# TC37XPD register map
Vendor: Infineon; Series: ATVMC; File version: 100
CPU: other r0p0, little endian, MPU, FPU, vendor SysTick, 4 interrupt priority bits
Registers are 32-bit, read-write, reset 0x0 unless marked. A register's access mark holds for its fields unless they carry their own. Offsets are from the block's base; [hi:lo] are bit positions; lines under a group give offsets from that group; {n}, {i} and the like mark numbered series.

## CBS
Base 0xF0000400
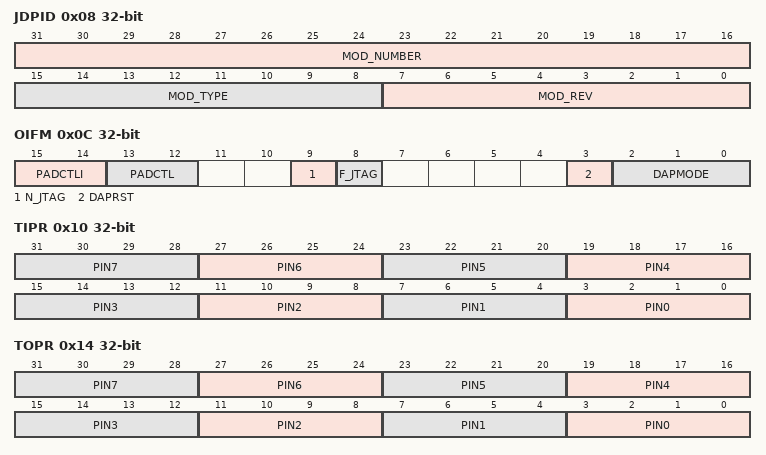
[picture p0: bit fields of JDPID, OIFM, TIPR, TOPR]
0x08 JDPID ro reset not defined — Module Identification Register resetvalue={PowerOn Reset:0x6360,Application Reset:0x0,Debug Reset:0x0,IOClient Reset:0x0}
  [31:16] MOD_NUMBER — Module Number MOD NUMBER
  [15:8] MOD_TYPE — Module Type MOD TYPE
  [7:0] MOD_REV — Module Revision MOD REV. This bit field indicates the revision number of the module implementation. It is just CROSSREFERENCE 7 0 .
0x0C OIFM reset not defined — OCDS Interface Mode Register resetvalue={PowerOn Reset:0x0,Application Reset:0x0,Debug Reset:0x0,IOClient Reset:0x0}
  [15:14] PADCTLI — Pad input threshold control for Debug Interface Pins. DAP pins always use TTL levels. This bits allows to set correct TTL levels even for 3.3V supply. Selection valid for DAP and DAPE pads.
  [13:12] PADCTL — Pad Control for Debug Interface Pins. padctl o Please consult the Data Sheet for the proper setting relative to the data rate. Selection valid for DAP and DAPE pads.
  [9] N_JTAG — No Switch to JTAG. jtag disable o
  [8] F_JTAG — Forced JTAG Mode. dap bypass o
  [3] DAPRST — DAPProtocol Clear DAPRST. Synchronous clear for the DAP state machine. See CROSSREFERENCE . Once set this bit is cleared by the hardware as soon as the DAP module has processed the reset request. As this is done with the DAP0 clock the time it takes is not predictable.
  [2:0] DAPMODE — DAPInterface Mode DAPMODE. DAPMODE mainly determines the number of pins allocated for the DAP Interface. The selected mode becomes active with the next received CROSSREFERENCE . The minimum number of dedicated DAP pins is device specific. If two pins are dedicated no SPD Single Pin DAP mode is needed offered. Please request DAP RST in parallel only if it is really needed and intended to force the selected mode and cut by this an already established tool connection. The underlying assumption is that the tool user is in control and the device should not sabotage tool access.
0x10 TIPR — TG Input Pins Routing resetvalue={Debug Reset:0x0}
  [4n+3:4n] PIN{n} (n=0..7) — Trigger Pin 7 to Trigger Line Routing
0x14 TOPR — TG Output Pins Routing resetvalue={Debug Reset:0x0}
  [4n+3:4n] PIN{n} (n=0..7) — Trigger Line to Trigger Pin 7 Routing
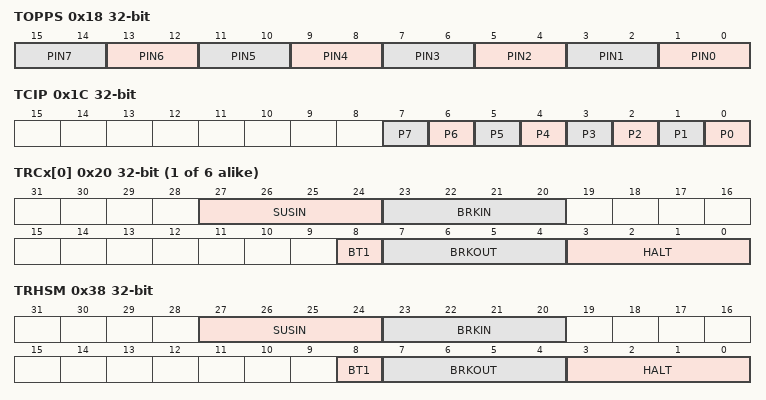
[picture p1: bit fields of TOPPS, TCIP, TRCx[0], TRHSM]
0x18 TOPPS — TG Output Pins Pulse Stretcher resetvalue={Debug Reset:0x0}
  [2n+1:2n] PIN{n} (n=0..7) — Pulse Stretch Control for Trigger Pin 7 PIN7
0x1C TCIP ro — TG Capture for TG Input Pins resetvalue={Debug Reset:0x0}
  [n] P{n} (n=0..7) — Capture of Trigger Input Pin 7 P7
{0x20+4i} TRCx[{i}] (i=0..5) reset not defined — TG Routing for CPU0 resetvalue={PowerOn Reset:0x0,Debug Reset:0x2,Debug Reset:0x0,Application Reset:0x0,IOClient Reset:0x0}
  [27:24] SUSIN — Trigger Line to SUSIN Routing SUSIN. Note Use TL1ST in case of Trigger Line 1.
  [23:20] BRKIN — Trigger Line to BRKIN Routing BRKIN
  [8] BT1 — BRKOUT to Trigger Line 1 Routing BT1. This option is available independent of the routing with BRKOUT . The use case is that BRKOUT is in addition a source for the suspend generation with Trigger Line 1.
  [7:4] BRKOUT — BRKOUT to Trigger Line Routing BRKOUT
  [3:0] HALT — HALT to Trigger Line Routing HALT
0x38 TRHSM — TG Routing for HSMControl resetvalue={Debug Reset:0x0}
  [27:24] SUSIN — Trigger Line to SUSIN Routing SUSIN. Note Use TL1ST in case of Trigger Line 1.
  [23:20] BRKIN — Trigger Line to BRKIN Routing BRKIN
  [8] BT1 — BRKOUT to Trigger Line 1 Routing BT1. BRKOUT signal is used in addition for suspend generation with Trigger Line 1.
  [7:4] BRKOUT — BRKOUT to Trigger Line Routing BRKOUT
  [3:0] HALT — HALT to Trigger Line Routing HALT
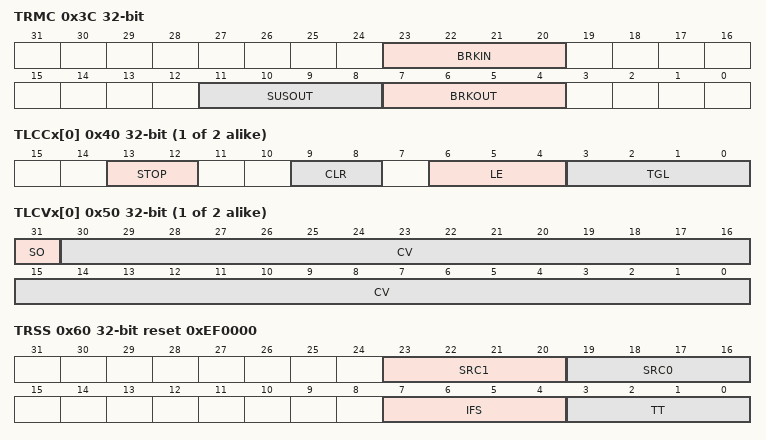
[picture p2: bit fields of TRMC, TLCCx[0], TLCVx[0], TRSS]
0x3C TRMC — TG Routing for MCDS Control resetvalue={Debug Reset:0x0}
  [23:20] BRKIN — Trigger Line to MCDS break in Routing BRKIN
  [11:8] SUSOUT — MCDS suspend out to Trigger Line Routing SUSOUT
  [7:4] BRKOUT — MCDS break out to Trigger Line Routing BRKOUT
{0x40+4i} TLCCx[{i}] (i=0..1) access per field — TG Line Counter Control resetvalue={Debug Reset:0x0}
  [13:12] STOP wo — Stop Counter s STOP
  [9:8] CLR wo — Clear and Enable Counter s CLR. Clears the counter value and enables a stopped counter. Counter reset state is stopped.
  [6:4] LE rw — Level or Edge Counting LE
  [3:0] TGL rw — Trigger Line to Counter Routing TGL
{0x50+4i} TLCVx[{i}] (i=0..1) ro — TG Line Counter Value resetvalue={Debug Reset:0x0}
  [31] SO — Sticky Overflow Bit SO. This bit is set by hardware when Count Value 30 0 is 0x7FFFFFFF. It is cleared by software like CV with TLCVx.CLR.
  [30:0] CV — Count Value CV
0x60 TRSS reset 0xEF0000 — TG Routing for Special Signals resetvalue={Debug Reset:0x0EF0000}
  [23:20] SRC1 — Trigger Line to SRC1 Interrupt Routing SRC1
  [19:16] SRC0 — Trigger Line to SRC1 Interrupt Routing SRC1
  [7:4] IFS — Trigger Line to Fault and Stress Injection Routing IFS. This bit field is not availavle in TC39x A Step.
  [3:0] TT — Trigger Line to Cerberus Triggered Transfer Routing TT
0x64 JTAGID reset not defined — JTAGDevice Identification Register resetvalue={PowerOn Reset:0x0,CFS Value:0x10207083,Application Reset:0x0,Debug Reset:0x0,IOClient Reset:0x0}
  [31:0] JTAG_ID — JTAGDevice ID JTAG ID
0x68 COMDATA reset not defined — Communication Mode Data Register resetvalue={PowerOn Reset:0x0,Application Reset:0x0,Debug Reset:0x0,IOClient Reset:0x0}
  [31:0] DATA — Read Write Data DATA. Data transferred by read write access executed by Cerberus in Communication mode.
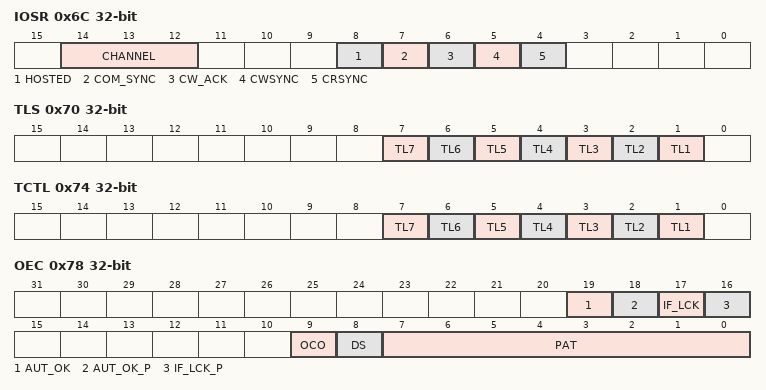
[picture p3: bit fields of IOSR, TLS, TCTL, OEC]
0x6C IOSR access per field reset not defined — IOClientStatus and Control Register resetvalue={PowerOn Reset:0x0,Application Reset:0x0,Debug Reset:0x0,IOClient Reset:0x0}
  [14:12] CHANNEL ro — Channel Indication CHANNEL. These bits can be used by the tool software to facilitate multiple users of the tool interface in Communication Mode While INT MOD is asserted this represents INTMOD . CHAN NEL CROSSREFERENCE . CHAN NEL otherwise.
  [8] HOSTED ro — Tool Interface in Use HOSTED. This bit is active when the DAP interface has received a CROSSREFERENCE .
  [7] COM_SYNC ro — Communication Mode Synchronization Flag COM SYNC. Can be used by the monitor program for higher level synchronization. While INT MOD is asserted this bit is set by INTMOD . SET CS and cleared by INTMOD . CLR CS . If INT MOD is de asserted this bit represents CROSSREFERENCE . COM SYNC directly.
  [6] CW_ACK wo — Communication Mode Write Acknowledge CW ACK. The on chip software uses this bit to clear CW SYNC after the data was taken from COMDATA . There is no automatic clear of CWS YNC as each read may potentially be cancelled by pipelining or bus re arbitration speculative reads .
  [5] CWSYNC ro — Communication Mode Write Sync Flag CWSYNC. Reflects the protocol state namely whether the host has posted data to be fetched. While INT MOD is de asserted this bit is set by writing the COMDATA register via the IO WRI TE WORD instruction. While INT MOD is asserted this bit is set by INTMOD . SET CWS . It is cleared by writing a 1 to CW ACK or by CROSSREFERENCE . COM RST 1 . Whenever this bit is set independent of INT MOD the OTGS is notified to optionally request an interrupt. This bit is not affected by changes of INT MOD itself.
  [4] CRSYNC ro — Communication Mode Read Sync Flag CRSYNC. Reflects the protocol state namely whether the host is waiting for data to be sent. While INT MOD is de asserted this bit is set by reading the COMDATA register via the IO READ WORD instruction. While INT MOD is asserted this bit is set by INTMOD . SET CRS . It is cleared by writing to COMDATA through the bus slave interface or by CROSSREFERENCE . COM RST The flag seen when INT MOD is asserted is not affected by CROSSREFERENCE . COM RST . . Whenever this bit is set independent of INT MOD the OTGS is notified to optionally request an interrupt. This bit is not affected by changes of INT MOD itself.
0x70 TLS ro — TG Line State resetvalue={Debug Reset:0x0}
  [n] TL{n} (n=1..7) — Current State of Trigger Line 7 TL7
0x74 TCTL ro — TG Capture for TG Lines resetvalue={Debug Reset:0x0}
  [n] TL{n} (n=1..7) — Capture of Trigger Line 7 TL7
0x78 OEC wo reset not defined — OCDS Enable Control Register resetvalue={PowerOn Reset:0x0,Application Reset:0x0,Debug Reset:0x0,IOClient Reset:0x0}
  [19] AUT_OK — Set Clear the Authorization OK Indication AUT OK. This bit is the only way to change the OSTATE . AUT OK by software.
  [18] AUT_OK_P — AUT OK Write Protection AUT OK P. Protect AUT OK against unintended changes.
  [17] IF_LCK — Set Clear Interface Locked Indication IF LCK. This bit is the only way to change the OSTATE . IF LCK by software.
  [16] IF_LCK_P — IF LCK Write Protection IF LCK P. Protect IF LCK against unintended changes.
  [9] OCO — OCDS Clock Off OCO. If OCDS is disabled again the OCDS clock can be optional switched off as well for power saving reasons e.g. for power measurements . The OCDS clock is automatically enabled with the OCDS. OSTATE . OCO shows the status. The OCDS clock can only be disabled if OCDS was already disabled before by another OEC register write.
  [8] DS — Disable OCDS DS. This bit allows the on chip software to disable the OCDS subsystem at any time. This is also good practice to do at the end of any debug session. To enable OCDS again the tool needs to repeat writing the enabling sequence into P AT .
  [7:0] PAT — OCDS Enabling Pattern PAT. The byte sequence described in CROSSREFERENCE must be written to this bit field sequentially to enable the OCDS subsystem.
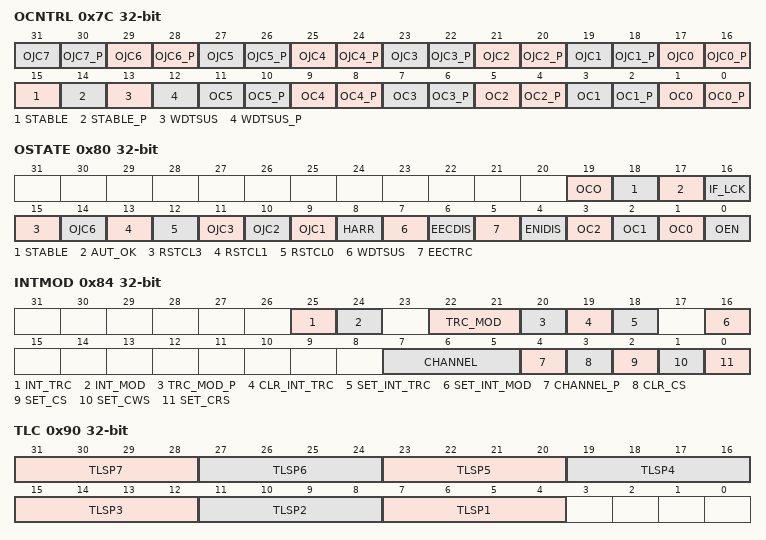
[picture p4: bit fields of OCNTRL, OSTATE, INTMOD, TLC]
0x7C OCNTRL wo reset not defined — OSCU Control Register resetvalue={PowerOn Reset:0x0,Application Reset:0x0,Debug Reset:0x0,IOClient Reset:0x0}
  [2n+17] OJC{n} (n=0..7) — Set Clear OCDS Control Bits IOClient Domain OJC7. These bits allow to change the associated OSTATE .OJCx bits by software. OSTATE .OJC0 is also called OSTATE . H ARR OEN protected . OSTATE .OJC4 is also called OSTATE . RSTCL0 OEN protected . OSTATE .OJC5 is also called OSTATE . RSTCL1 . OSTATE .OJC7 is also called OSTATE . RSTCL3 OEN protected . OSTATE .OJCx can also be set cleared by the IOClient via the CROSSREFERENCE register. The IOClient has the higher priority.
  [2n+16] OJC{n}_P (n=0..7) — OJC7 Write Protection OJC7 P. Protect OSTATE .OJCx against unintended changes.
  [15] STABLE — InitializeApplication ResetIndication STABLE. This bit is the only way to change the OSTATE . STA BLE bit by software.
  [14] STABLE_P — STABLE Write Protection STABLE P. Protect OSTATE . STA BLE against unintended changes.
  [13] WDTSUS — Set Clear Watchdog Timer Suspension Control WDTSUS. This bit OEN protected is the only way to change the OSTATE . WD TSUS by software.
  [12] WDTSUS_P — WDTSUS Write Protection WDTSUS P. Protect OSTATE . W DTSUS against unintended changes.
  [2n+1] OC{n} (n=0..5) — Set Clear OCDS Control Bits Bus Domain OC5. These bits allow to change the associated OSTATE .OCx bits by software. OSTATE .OC3 is also called OSTATE . ENIDIS OEN protected . OSTATE .OC4 is also called OSTATE . EECTRC OEN protected . OSTATE .OC5 is also called OSTATE . EECDIS OEN protected .
  [2n] OC{n}_P (n=0..5) — OC5 Write Protection OC5 P. Protect OSTATE .OCx against unintended changes.
0x80 OSTATE ro reset not defined — OSCUStatus Register resetvalue={PowerOn Reset:0x10000,Application Reset:0x0,Debug Reset:0x0,IOClient Reset:0x0}
  [19] OCO — OCDS debug resource Clock On Indication OCO. This bit is used by the tool to detect the status of the OCDS debug resource clock on control register. Set and clear is done through the OEC . OCO register.
  [18] STABLE — Application Reset Indication STABLE. This bit is used by the tool to detect Application Reset s. It has no direct hardware effects. Set and clear is done through the OCNTRL register.
  [17] AUT_OK — Authorization OK Indication AUT OK. This bit is used by the software inside the device to store the higher level CROSSREFERENCE access right status of the IOClient through Application Reset s. It has no direct hardware effects. Set and clear is done through the OEC register.
  [16] IF_LCK — Interface Locked Indication IF LCK. This bit is used by the software inside the device to control the access right of the IOClient. Set and clear is done through the OEC register. Overruling by HSM is not visible in this bit.
  [15] RSTCL3 — OCDS Application Reset Request RSTCL3. Can be set and cleared either with the associated OCNTRL .OJC7 via the system bus or CROSSREFERENCE .OJC7 bits. The IOClient has the higher priority. The Kernel clock must be running to change this bit. A request from the IOClient however is stored until this is the case. If the last set operation was done via OCNTRL this bit is automatically cleared by the next Application Reset .
  [14] OJC6 — OCDS Control Bits IOClient Domain OJC6. Are used for device specific OCDS configuration purposes. As these bits can be set by the IOClient regardless of IF LCK and O EN make sure not to create a security hole in usage. They can be set and cleared either with the associated OCNTRL .OJCx via the system bus or CROSSREFERENCE .OJCx bits. The IOClient however has the higher priority. The Kernel clock must be running to change these bits. A request from the IOClient however is stored until this is the case.
  [13] RSTCL1 — OCDS Debug Reset Request RSTCL1. Can be set and cleared either with the associated OCNTRL .OJC5 via the system bus or CROSSREFERENCE .OJC5 bits. The IOClient has the higher priority. The Kernel clock must be running to change this bit. A request from the IOClient however is stored until this is the case. If the last set operation was done via OCNTRL this bit is automatically cleared by the next Application Reset . The requested Debug Reset will not clear this request automatically a second write to OCNTRL is required to terminate the Debug Reset .
  [12] RSTCL0 — OCDS System Reset Request RSTCL0. Can be set either with the associated OCNTRL .OJC4 via the system bus or CROSSREFERENCE .OJC4 bits. The IOClient has the higher priority. The Kernel clock must be running to change this bit. A request from the IOClient however is stored until this is the case. This bit is automatically cleared by the next System Reset.
  [11] OJC3 — OCDS Control Bits IOClient Domain OJC3. Are used for device specific OCDS configuration purposes. As these bits can be set by the IOClient regardless of IF LCK and O EN make sure not to create a security hole in usage. They can be set and cleared either with the associated OCNTRL .OJCx via the system bus or CROSSREFERENCE .OJCx bits. The IOClient however has the higher priority. The Kernel clock must be running to change these bits. A request from the IOClient however is stored until this is the case.
  [10] OJC2 — OCDS Control Bits IOClient Domain OJC2. Are used for device specific OCDS configuration purposes. As these bits can be set by the IOClient regardless of IF LCK and O EN make sure not to create a security hole in usage. They can be set and cleared either with the associated OCNTRL .OJCx via the system bus or CROSSREFERENCE .OJCx bits. The IOClient however has the higher priority. The Kernel clock must be running to change these bits. A request from the IOClient however is stored until this is the case.
  [9] OJC1 — OCDS Control Bits IOClient Domain OJC1. Are used for device specific OCDS configuration purposes. As these bits can be set by the IOClient regardless of IF LCK and O EN make sure not to create a security hole in usage. They can be set and cleared either with the associated OCNTRL .OJCx via the system bus or CROSSREFERENCE .OJCx bits. The IOClient however has the higher priority. The Kernel clock must be running to change these bits. A request from the IOClient however is stored until this is the case.
  [8] HARR — Halt after Reset Request HARR. This bit tells the Startup Software to stop prior to entering the application code. It can be set cleared with either OCNTRL .OJC0 via the Bus Slave Interface or CROSSREFERENCE .OJC0 via the IOClient . The IOClient however has the higher priority. The Kernel clock must be running to change this bit. A request from the IOClient however is stored until this is the case.
  [7] WDTSUS — Control of Watchdog Timer WDT Suspension WDTSUS. This bit determines the behavior of the watchdog timers when the system is running with OCDS enabled. Set and clear is done by OCNTRL . WD TSUS .
  [6] EECDIS — Emulation Logic Disable EECDIS. If the features of the EEC are not needed the complete EEC can be switched off with this control bit. Can be set and cleared with OCNTRL .OC5 only. Both tracing and calibration overlay require the EEC to be turned on.
  [5] EECTRC — On Chip Trace Enable EECTRC. The trace ports of all cores are normally turned off for security and power consumption reasons. Only if tracing is desired the ports are globally enabled with this control bit. Can be set and cleared with OCNTRL .OC4 only. Specific enables for single trace interfaces will be added inside MCDS.
  [4] ENIDIS — OCDS ENDINIT Protection Override ENIDIS. To modify ENDINIT protected register bits via Cerberus it would be dangerous to tamper with the protection logic controlled by a watchdog timer. This control bit allows to overrule the SCU. Can be set and cleared with OCNTRL .OC3 only.
  [3] OC2 — OCDS Control Bits System Bus Domain OC2. Are used for device specific OCDS configuration purposes. They can be set and cleared with the associated OCNTRL .OCx bits.
  [2] OC1 — OCDS Control Bits System Bus Domain OC2. Are used for device specific OCDS configuration purposes. They can be set and cleared with the associated OCNTRL .OCx bits.
  [1] OC0 — OCDS Control Bits System Bus Domain OC2. Are used for device specific OCDS configuration purposes. They can be set and cleared with the associated OCNTRL .OCx bits.
  [0] OEN — OCDS Enabled Flag OEN. This bit enables the OCDS functionality of the complete device. Set and clear is done through the OEC register. This flag does not show any overruling by the HSM .
0x84 INTMOD access per field reset not defined — Internal Mode Status and Control Register resetvalue={PowerOn Reset:0x0,Application Reset:0x0,Debug Reset:0x0,IOClient Reset:0x0}
  [25] INT_TRC ro — Internally Controlled Triggered Transfer Enable INT TRC. This bit tells whether an Internally Controlled Triggered Transfer is currently enabled. Set by SET INT TRC Cleared by CLR INT TRC. This bit is just CROSSREFERENCE . EX B US TRC if INT MOD is de asserted.
  [24] INT_MOD ro — Internal Mode Enabled Flag INT MOD. This bit reflects whether the Internal Mode is currently active. Set by SET IN T MOD Cleared by Application Reset OCDS disable or any IOClient access
  [22:21] TRC_MOD rw — Data Size Definition for Triggered Transfer TRC MOD. The kind of bus access used during an Internally Controlled Triggered Transfer is defined by this bit field 1 If INT MOD is de asserted this bit field is set to 00 . This value will also be present whenever Internal Mode is entered.
  [20] TRC_MOD_P wo — TRC MOD Write Protection TRC MOD P. Protect TRC MOD against unintended changes.
  [19] CLR_INT_TRC wo — Disable Internally Controlled Triggered Transfer CLR INT TRC
  [18] SET_INT_TRC wo — Enable Internally Controlled Triggered Transfer SET INT TRC. See CROSSREFERENCE for a description of the Triggered Transfer modes.
  [16] SET_INT_MOD wo — Enter Internal Mode SET INT MOD. This bit is the only way to enter Internal Mode.
  [7:5] CHANNEL rw — Channel Indication CHANNEL. These bits are just written into the IOSR . CHAN NEL bit field in Internal Mode when CHANNEL P is held 160 8217 1 8217 concurrently 1 . Upon reading the current setting of IOSR . CHAN NEL is returned. If INT MOD is de asserted this is the value present in CROSSREFERENCE . CHAN NEL
  [4] CHANNEL_P wo — CHANNEL Write Protection CHANNEL P. Protect CHA NNEL against unintended changes.
  [3] CLR_CS wo — Clear Communication Synchronization Flag CLR CS. Used by the monitor program to clear the higher level Communication Mode sync bit in Internal Mode.
  [2] SET_CS wo — Set Communication Synchronization Flag SET CS. Used by the monitor program to set the higher level Communication Mode sync bit in Internal Mode.
  [1] SET_CWS wo — Set Write Sync Flag SET CWS. Used by the monitor program to set the Write Sync Flag in Internal Mode.
  [0] SET_CRS wo — Set Read Sync Flag SET CRS. Used by the monitor program to set the Read Sync Flag in Internal Mode.
0x88 ICTSA reset not defined — Internally Controlled Trace Source Register resetvalue={PowerOn Reset:0x0,Application Reset:0x0,Debug Reset:0x0,IOClient Reset:0x0}
  [31:0] ADDR — Source Address ADDR. This address is used by Cerberus to read data size depending on INTMOD . TRC MOD when a triggered transfer takes place in internal mode.
0x8C ICTTA reset not defined — Internally Controlled Trace Destination Register resetvalue={PowerOn Reset:0x10F068,Application Reset:0x10F068,Debug Reset:0x0,IOClient Reset:0x0}
  [31:0] ADDR — Destination Address ADDR. This address is used by Cerberus to write data size depending on INTMOD . TRC MOD when a triggered transfer takes place in internal mode.
0x90 TLC — TG Line Control resetvalue={Debug Reset:0x0}
  [4n+3:4n] TLSP{n} (n=1..7) — TG Line Signal Processing TLSP7
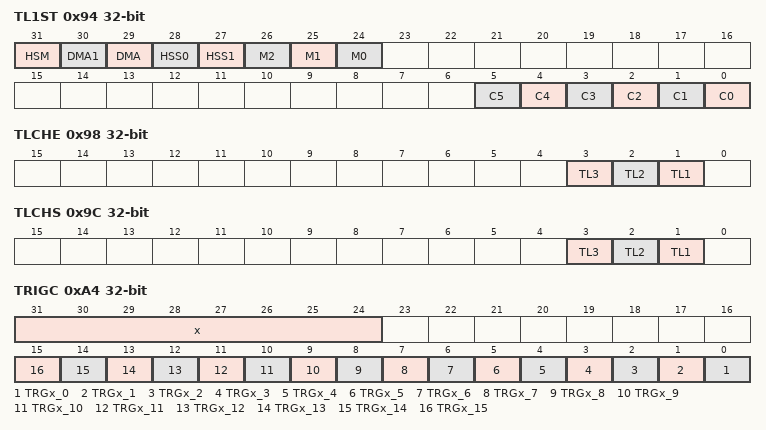
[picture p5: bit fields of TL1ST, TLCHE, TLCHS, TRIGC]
0x94 TL1ST — TG Line 1 Suspend Targets resetvalue={Debug Reset:0x0}
  [31] HSM — HSM as Suspend Target HSM
  [30] DMA1 — DMA as Suspend Target DMA1. Prepared Reserved for future use with DMA
  [29] DMA — DMA as Suspend Target DMA
  [28] HSS0 — HSSL0 as Suspend Target HSS0
  [27] HSS1 — HSSL1 as Suspend Target HSS1
  [26] M2 — Master 2 as Suspend Target. Prepared for not yet known bus masters on future SoCs which need suspend control. Once used in the future the bit will get the name of the master.
  [25] M1 — Master 1 as Suspend Target. Prepared for not yet known bus masters on future SoCs which need suspend control. Once used in the future the bit will get the name of the master.
  [24] M0 — Master 0 as Suspend Target. Prepared for not yet known bus masters on future SoCs which need suspend control. Once used in the future the bit will get the name of the master.
  [n] C{n} (n=0..5) — CPU5 as Suspend Target C5
0x98 TLCHE — TG Line Capture and Hold Enable resetvalue={Debug Reset:0x0}
  [3] TL3 — Capture and Hold Enable for Trigger Line 3 TL3
  [2] TL2 — Capture and Hold Enable for Trigger Line 3 TL3
  [1] TL1 — Capture and Hold Enable for Trigger Line 3 TL3
0x9C TLCHS wo — TG Line Capture and Hold Clear resetvalue={Debug Reset:0x0}
  [3] TL3 — Capture and Hold Clear for Trigger Line 3 TL3
  [2] TL2 — Capture and Hold Clear for Trigger Line 3 TL3
  [1] TL1 — Capture and Hold Clear for Trigger Line 3 TL3
0xA0 TRIGS wo reset not defined — Set Trigger to Host Register resetvalue={PowerOn Reset:0x0,Application Reset:0x0,Debug Reset:0x0,IOClient Reset:0x0}
  [7:0] BITNUM — Service Request Bit Number to Set BITNUM. The bit TRGx y of register TRIGx is set with x BITNUM div 16 and y BITNUM mod 16 . LOST SEQUENCE DEFINITION
0xA4 TRIGC ro reset not defined — Clear Trigger to Host Register resetvalue={PowerOn Reset:0x0,Application Reset:0x0,Debug Reset:0x0,IOClient Reset:0x0}
  [31:24] x — Index of most important register TRIGx x. For TRIGx the highest x available x 5 .
  [n] TRGx_{n} (n=0..15) — Request Bits of most important register TRIGx TRGx 15. From all TRIGx registers with any TRG bit set the TRIGx with the lowest x is cleared. If any bit s are set concurrently these bits will not be cleared but end up in the set state.
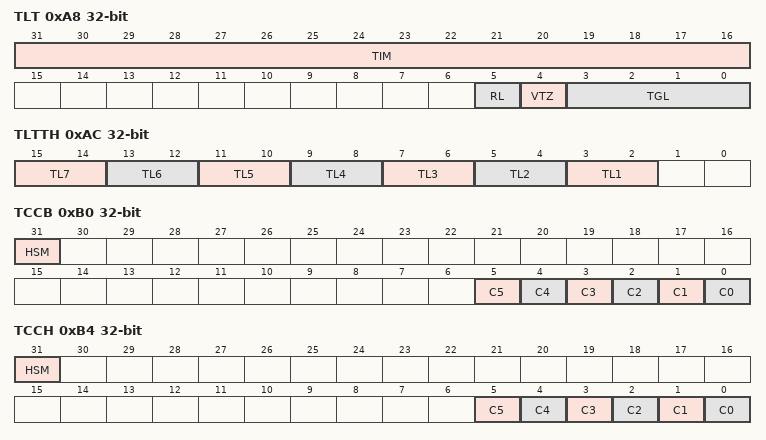
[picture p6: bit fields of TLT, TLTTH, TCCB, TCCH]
0xA8 TLT — TG Line Timer resetvalue={Debug Reset:0x0}
  [31:16] TIM — Timer Value TIM. Timer value which is automatically decremented if not 0. The timer frequency is fixed to f SPB divided by 4.
  [5] RL — Reload Timer RL
  [4] VTZ — TG Line Value when Timer Value is Zero VTZ
  [3:0] TGL — Timer to Trigger Line Routing TGL
0xAC TLTTH — TG Lines for Trigger to Host resetvalue={Debug Reset:0x0}
  [2n+1:2n] TL{n} (n=1..7) — TG Line Enabling for Trigger to Host TRIG TL7
0xB0 TCCB ro — TG Capture for Cores BRKOUT resetvalue={Debug Reset:0x0}
  [31] HSM — Capture of BRKOUT Signal ofHSM HSM
  [n] C{n} (n=0..5) — Capture of BRKOUT Signal of CPU5 C5
0xB4 TCCH ro — TG Capture for Cores HALT resetvalue={Debug Reset:0x0}
  [31] HSM — Capture of HALT Signal ofHSM HSM
  [n] C{n} (n=0..5) — Capture of HALT Signal of CPU5 C5
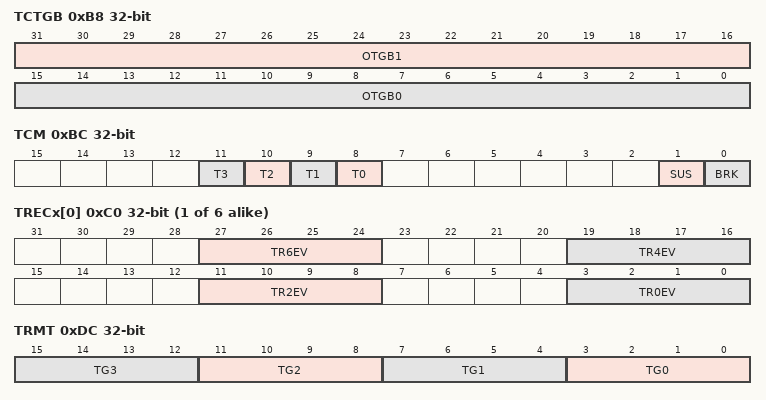
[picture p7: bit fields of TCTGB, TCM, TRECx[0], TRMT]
0xB8 TCTGB ro — TG Capture for OTGB0 1 resetvalue={Debug Reset:0x0}
  [31:16] OTGB1 — Capture Bits for OTGB1 OTGB1. If a bit is set the associated OTGB1 signal was active high since last read.
  [15:0] OTGB0 — Capture Bits for OTGB0 OTGB0. If a bit is set the associated OTGB0 signal was active high since last read.
0xBC TCM ro — TG Capture for MCDS resetvalue={Debug Reset:0x0}
  [n+8] T{n} (n=0..3) — Capture of MCDS trig out 3 T3
  [1] SUS — Capture of MCDS suspend out SUS
  [0] BRK — Capture of MCDS break out BRK
{0xC0+4i} TRECx[{i}] (i=0..5) — TG Routing Events of CPU0 resetvalue={Debug Reset:0x0}
  [27:24] TR6EV — TRxEVT to Trigger Line Routing TR6EV
  [19:16] TR4EV — TRxEVT to Trigger Line Routing TR4EV
  [11:8] TR2EV — TRxEVT to Trigger Line Routing TR2EV
  [3:0] TR0EV — TRxEVT to Trigger Line Routing TR0EV
0xDC TRMT — TG Routing for MCDS Triggers resetvalue={Debug Reset:0x0}
  [4n+3:4n] TG{n} (n=0..3) — MCDS trig out 3 to Trigger Line Routing TG3
{0xE0+8i} TRTGB[{i}] (i=0..1) group
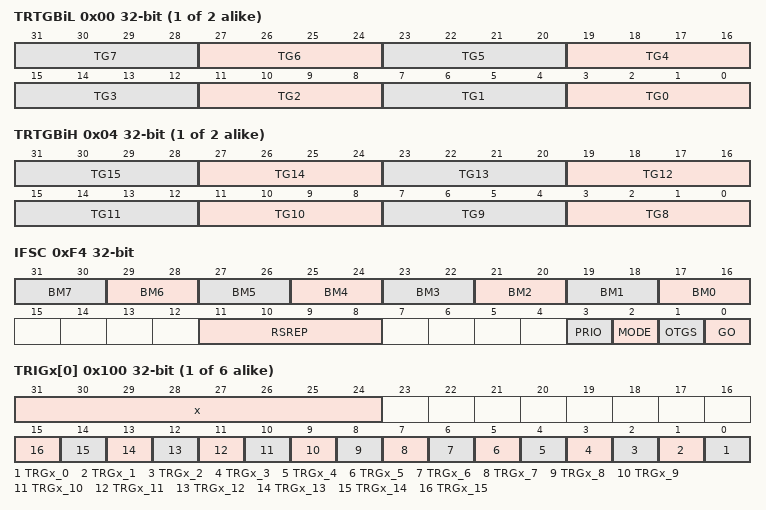
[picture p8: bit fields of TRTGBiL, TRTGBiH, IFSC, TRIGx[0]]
  0x00 TRTGBiL — TG Routing for OTGBi Bits 7 0 resetvalue={Debug Reset:0x0}
    [4n+3:4n] TG{n} (n=0..7) — OTGBi Bit 7 to Trigger Line Routing TG7
  0x04 TRTGBiH — TG Routing for OTGBi Bits 15 8 resetvalue={Debug Reset:0x0}
    [4n-29:4n-32] TG{n} (n=8..15) — OTGBi Bit 15 to Trigger Line Routing TG15
0xF0 IFSA — IFS Address Register resetvalue={Debug Reset:0x0}
  [31:0] ADDR — Address for FI SI Accesses ADDR. In case of FI the lowest two bits address the byte within the 32 160 bit word which is used for the RMW access. In case of SI the lowest two bits are ignored.
0xF4 IFSC access per field — IFS Control Register resetvalue={Debug Reset:0x0}
  [2n+17:2n+16] BM{n} rw (n=0..7) — Fault Injection Bit Manipulation BM7. Controls the manipulation of bit x within the byte addressed by IFSA . The lowest two bits of IFSA determine the byte within the 32 bit word of the RMW operation. All other bytes of the word are unchanged.
  [11:8] RSREP rw — Read Stress Repetitions. The value 0 means just one SI read the value 15 means 16 reads overall
  [3] PRIO rw — Bus Master Priority PRIO
  [2] MODE rw — Stress or Fault Injection Mode MODE
  [1] OTGS rw — Injection Trigger by OTGS OTGS
  [0] GO wo — Injection Trigger GO. This bit shall be gated by OCDS enable.
{0x100+4i} TRIGx[{i}] (i=0..5) ro reset not defined — Trigger to Host Register 0 resetvalue={PowerOn Reset:0x0,Application Reset:0x0,Debug Reset:0x0,IOClient Reset:0x0}
  [31:24] x — TRIG register number x
  [n] TRGx_{n} (n=0..15) — Service Request Bits TRGx 15. Are used by the tool software running on the SoC to request specific services e.g. upload measurement data block from the host. The bit is set by writing the correct bit number into the TRIGS register. To set TRGx y the number x 16 y must be written to TRIGS . All request bits of a specific TRIGx are cleared only when from all TRIG registers with any TRG bit set TRIGx happens to have the lowest x and either TRIGC is read or the IO READ TRIG instruction is executed. In case of concurrent set and clear the affected bit s will remain set. Bit numbers higher than 95 highest TRIGx register stuck 0 .
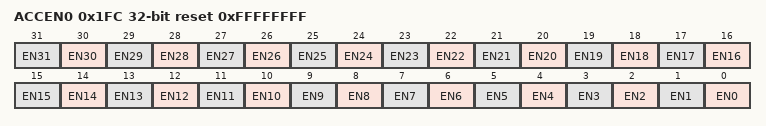
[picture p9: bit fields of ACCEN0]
0x1FC ACCEN0 reset 0xFFFFFFFF — Access Enable Register 0 resetvalue={Application Reset:0x0FFFFFFFF}
  [n] EN{n} (n=0..31) — Access Enable for Master TAG ID 31 EN31. This bit enables write access to the module kernel addresses for transactions with the Master TAG ID n
